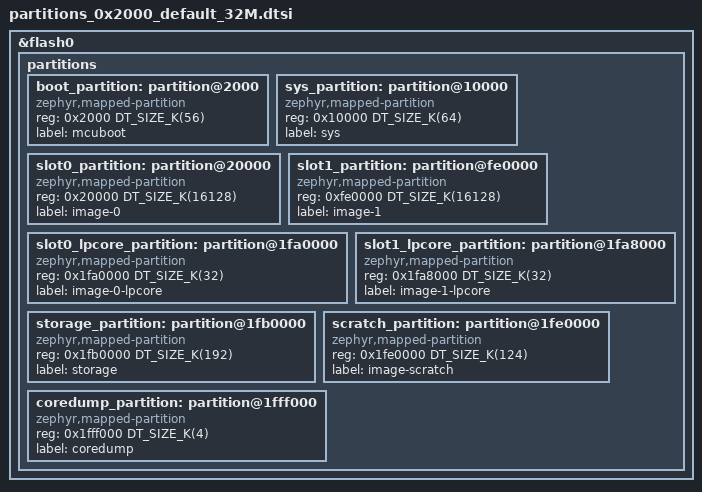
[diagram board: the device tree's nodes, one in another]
/*
 * Copyright (c) 2026 Hongquan Li
 *
 * SPDX-License-Identifier: Apache-2.0
 *
 * ESP32-P4 partition table with 0x2000 boot offset.
 * The ROM reserves the first 2 flash sectors (8KB).
 */

&flash0 {
	partitions {
		ranges;
		#address-cells = <1>;
		#size-cells = <1>;

		boot_partition: partition@2000 {
			compatible = "zephyr,mapped-partition";
			reg = <0x2000 DT_SIZE_K(56)>;
			label = "mcuboot";
		};

		sys_partition: partition@10000 {
			compatible = "zephyr,mapped-partition";
			reg = <0x10000 DT_SIZE_K(64)>;
			label = "sys";
		};

		slot0_partition: partition@20000 {
			compatible = "zephyr,mapped-partition";
			reg = <0x20000 DT_SIZE_K(16128)>;
			label = "image-0";
		};

		slot1_partition: partition@fe0000 {
			compatible = "zephyr,mapped-partition";
			reg = <0xfe0000 DT_SIZE_K(16128)>;
			label = "image-1";
		};

		slot0_lpcore_partition: partition@1fa0000 {
			compatible = "zephyr,mapped-partition";
			reg = <0x1fa0000 DT_SIZE_K(32)>;
			label = "image-0-lpcore";
		};

		slot1_lpcore_partition: partition@1fa8000 {
			compatible = "zephyr,mapped-partition";
			reg = <0x1fa8000 DT_SIZE_K(32)>;
			label = "image-1-lpcore";
		};

		storage_partition: partition@1fb0000 {
			compatible = "zephyr,mapped-partition";
			reg = <0x1fb0000 DT_SIZE_K(192)>;
			label = "storage";
		};

		scratch_partition: partition@1fe0000 {
			compatible = "zephyr,mapped-partition";
			reg = <0x1fe0000 DT_SIZE_K(124)>;
			label = "image-scratch";
		};

		coredump_partition: partition@1fff000 {
			compatible = "zephyr,mapped-partition";
			reg = <0x1fff000 DT_SIZE_K(4)>;
			label = "coredump";
		};
	};
};

/* Remaining flash size is 0kB
 * Last used address is 0x1FFFFFF
 */
